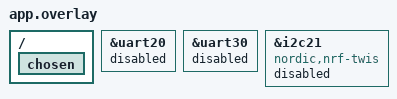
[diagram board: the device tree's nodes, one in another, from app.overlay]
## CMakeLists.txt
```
cmake_minimum_required(VERSION 3.20.0)
find_package(Zephyr REQUIRED HINTS $ENV{ZEPHYR_BASE})
project(m24_twi_driver_contract)
target_sources(app PRIVATE src/main.cpp)
```

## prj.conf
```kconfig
CONFIG_ZTEST=y
CONFIG_CPP=y
CONFIG_STD_CPP17=y
CONFIG_CPP_EXCEPTIONS=n
CONFIG_CPP_RTTI=n
CONFIG_ZTEST_NO_YIELD=y

CONFIG_CONSOLE=n
CONFIG_SERIAL=n
CONFIG_PRINTK=n
CONFIG_LOG=n

CONFIG_NUCODE_ARDUINO_CORE=y
CONFIG_NUCODE_ARDUINO_RUNTIME=n
CONFIG_NUCODE_ARDUINO_API=y
CONFIG_NUCODE_ARDUINO_IO_OWNERSHIP=y
CONFIG_NUCODE_ARDUINO_IO_RESOURCE_SLOTS=64
CONFIG_NUCODE_ARDUINO_GPIO=y
CONFIG_NUCODE_ARDUINO_CONNECTOR_GPIO=y
CONFIG_NUCODE_ARDUINO_DAP_UART_GPIO_PINS=y
CONFIG_NUCODE_ARDUINO_INTERRUPTS=n
CONFIG_NUCODE_ARDUINO_TIME=n
CONFIG_NUCODE_ARDUINO_SERIAL=n
CONFIG_NUCODE_ARDUINO_SERIAL_FABRIC=y
CONFIG_NUCODE_ARDUINO_SERIAL_FABRIC_TWIM=y
CONFIG_NUCODE_ARDUINO_SERIAL_FABRIC_TWIS=y
CONFIG_NUCODE_ARDUINO_WIRE=n
CONFIG_NUCODE_ARDUINO_SPI=n
CONFIG_NUCODE_ARDUINO_ADC=n
CONFIG_NUCODE_ARDUINO_PWM=n

CONFIG_COMMON_LIBC_MALLOC_ARENA_SIZE=8192
CONFIG_MAIN_STACK_SIZE=4096
CONFIG_TEST_EXTRA_STACK_SIZE=2048
```

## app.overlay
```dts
/** @brief Direct nrfx TWI adapters가 serial block IRQ를 단독 소유합니다. */
#include <nucode/nu54dk-arduino-pins.dtsi>

/ {
    chosen {
        /delete-property/ zephyr,console;
        /delete-property/ zephyr,shell-uart;
        /delete-property/ zephyr,uart-mcumgr;
        /delete-property/ zephyr,bt-mon-uart;
        /delete-property/ zephyr,bt-c2h-uart;
    };
};

&uart20 {
    status = "disabled";
};

&uart30 {
    status = "disabled";
};

/* Keep it disabled, but satisfy nrfx TWIS's generated compatibility gate. */
&i2c21 {
    compatible = "nordic,nrf-twis";
    status = "disabled";
};
```

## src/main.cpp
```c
/**
 * @file main.cpp
 * @brief M24 TWIM/TWIS 전 instance adapter와 DMA 경계를 검증합니다.
 *
 * SPDX-License-Identifier: MIT
 */

#include <nucode/SerialFabric.h>

#include <variant.h>

#include <zephyr/ztest.h>

#include <cstddef>
#include <cstdint>

namespace
{
    using namespace nucode::arduino;

    alignas(4) std::uint8_t workspaces[8][128]{};

    const SerialSignalPin p1_pins[] = {
        {SerialSignal::sda, PIN_P1_10},
        {SerialSignal::scl, PIN_P1_14},
    };
    const SerialSignalPin p0_pins[] = {
        {SerialSignal::sda, PIN_P0_00},
        {SerialSignal::scl, PIN_P0_01},
    };
    const SerialSignalPin pmic_pins[] = {
        {SerialSignal::sda, PIN_P1_02},
        {SerialSignal::scl, PIN_P1_03},
    };

    SerialFabricConfiguration configuration(std::uint8_t instance, std::size_t workspace)
    {
        static SerialDmaWorkspace dma[8];
        dma[workspace] = {workspaces[workspace], sizeof(workspaces[workspace])};
        if (instance == 30U)
        {
            return {SerialRouteClass::p0_flexible,
                    SerialElectricalProfile::dap_uart_disabled,
                    p0_pins,
                    2U,
                    &dma[workspace],
                    1U};
        }
        return {SerialRouteClass::p1_flexible,
                SerialElectricalProfile::connector_fixture,
                p1_pins,
                2U,
                &dma[workspace],
                1U};
    }
} // namespace

ZTEST(m24_twi_driver_contract, test_all_eight_adapters_stage_exact_routes)
{
    const std::uint8_t instances[] = {20U, 21U, 22U, 30U};
    for (std::size_t index = 0U; index < 4U; ++index)
    {
        auto *const controller = serialFabric().twim(instances[index]);
        auto *const target = serialFabric().twis(instances[index]);
        zassert_not_null(controller, "TWIM handle 누락");
        zassert_not_null(target, "TWIS handle 누락");
        zassert_equal(controller->configure({TwiFabricFrequency::fast}),
                      SerialFabricResult::success, "TWIM configure 실패");
        zassert_equal(target->configure({0x42U, 0x43U, false}), SerialFabricResult::success,
                      "TWIS configure 실패");
        zassert_equal(controller->stage(configuration(instances[index], index)),
                      SerialFabricResult::success, "TWIM stage 실패");
        zassert_equal(target->stage(configuration(instances[index], index + 4U)),
                      SerialFabricResult::success, "TWIS stage 실패");
    }
}

ZTEST(m24_twi_driver_contract, test_pmic_profile_is_controller_read_only)
{
    SerialDmaWorkspace dma{workspaces[0], sizeof(workspaces[0])};
    const SerialFabricConfiguration config{SerialRouteClass::p1_flexible,
                                           SerialElectricalProfile::pmic_read_only,
                                           pmic_pins,
                                           2U,
                                           &dma,
                                           1U};
    auto *const target = serialFabric().twis(20U);
    zassert_equal(target->stage(config), SerialFabricResult::unsafe_electrical_profile,
                  "TWIS가 온보드 PMIC net 구동을 허용했습니다.");
}

ZTEST(m24_twi_driver_contract, test_inactive_dma_operations_fail_closed)
{
    auto *const controller = serialFabric().twim(21U);
    auto *const target = serialFabric().twis(21U);
    zassert_equal(controller->transferAsync(0x42U, workspaces[0], 1U, workspaces[0] + 4U, 4U),
                  SerialFabricResult::wrong_state, "inactive TWIM transfer를 허용했습니다.");
    zassert_equal(target->queueBuffers(workspaces[1], 8U, workspaces[1] + 16U, 8U),
                  SerialFabricResult::wrong_state, "inactive TWIS buffer를 허용했습니다.");
    TwiFabricEvent event{};
    zassert_false(controller->takeEvent(event), "가짜 TWIM event가 있습니다.");
    zassert_false(target->takeEvent(event), "가짜 TWIS event가 있습니다.");
}

ZTEST_SUITE(m24_twi_driver_contract, nullptr, nullptr, nullptr, nullptr, nullptr);
```
